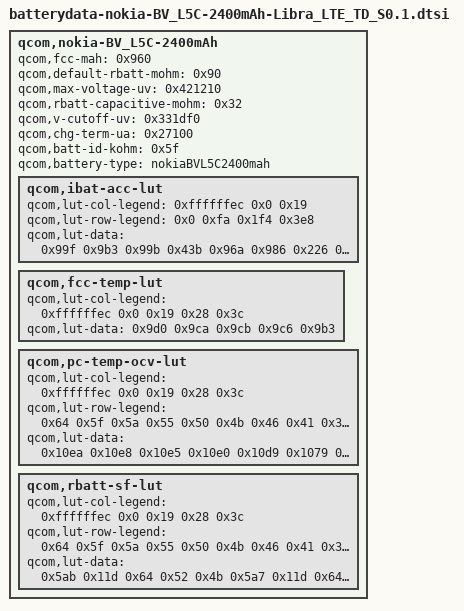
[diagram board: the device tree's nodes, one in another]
/* Copyright (c) 2013, The Linux Foundation. All rights reserved.
 *
 * This program is free software; you can redistribute it and/or modify
 * it under the terms of the GNU General Public License version 2 and
 * only version 2 as published by the Free Software Foundation.
 *
 * This program is distributed in the hope that it will be useful,
 * but WITHOUT ANY WARRANTY; without even the implied warranty of
 * MERCHANTABILITY or FITNESS FOR A PARTICULAR PURPOSE.  See the
 * GNU General Public License for more details.
 */

qcom,nokia-BV_L5C-2400mAh {
			qcom,fcc-mah = <0x960>;
			qcom,default-rbatt-mohm = <0x90>;
			qcom,max-voltage-uv = <0x421210>;
			qcom,rbatt-capacitive-mohm = <0x32>;
			qcom,v-cutoff-uv = <0x331df0>;
			qcom,chg-term-ua = <0x27100>;
			qcom,batt-id-kohm = <0x5f>;
			qcom,battery-type = "nokiaBVL5C2400mah";

			qcom,ibat-acc-lut {
				qcom,lut-col-legend = <0xffffffec 0x0 0x19>;
				qcom,lut-row-legend = <0x0 0xfa 0x1f4 0x3e8>;
				qcom,lut-data = <0x99f 0x9b3 0x99b 0x43b 0x96a 0x986 0x226 0x8b5 0x979 0x33 0x62e 0x954>;
			};

			qcom,fcc-temp-lut {
				qcom,lut-col-legend = <0xffffffec 0x0 0x19 0x28 0x3c>;
				qcom,lut-data = <0x9d0 0x9ca 0x9cb 0x9c6 0x9b3>;
			};

			qcom,pc-temp-ocv-lut {
				qcom,lut-col-legend = <0xffffffec 0x0 0x19 0x28 0x3c>;
				qcom,lut-row-legend = <0x64 0x5f 0x5a 0x55 0x50 0x4b 0x46 0x41 0x3c 0x37 0x32 0x2d 0x28 0x23 0x1e 0x19 0x14 0x10 0xd 0xb 0xa 0x9 0x8 0x7 0x6 0x5 0x4 0x3 0x2 0x1 0x0>;
				qcom,lut-data = <0x10ea 0x10e8 0x10e5 0x10e0 0x10d9 0x1079 0x1099 0x109e 0x109b 0x1096 0x1034 0x1060 0x1064 0x1062 0x105e 0xffe 0x102a 0x102c 0x102a 0x1026 0xfc8 0xff8 0xffa 0xff7 0xff2 0xf66 0xfc6 0xfcc 0xfc9 0xfc2 0xf3e 0xf72 0xf8e 0xf93 0xf96 0xf16 0xf4d 0xf72 0xf71 0xf6f 0xef6 0xf2e 0xf4a 0xf4c 0xf4a 0xee5 0xf0e 0xf1c 0xf22 0xf22 0xed8 0xef2 0xef9 0xefa 0xef8 0xecc 0xedc 0xee2 0xee2 0xee2 0xec0 0xecd 0xed2 0xed2 0xed0 0xeb4 0xec4 0xec4 0xec4 0xec2 0xea7 0xebc 0xebc 0xeb8 0xeb2 0xe98 0xeb2 0xeb4 0xeac 0xe9f 0xe88 0xea1 0xea4 0xe9a 0xe8b 0xe78 0xe88 0xe8a 0xe80 0xe73 0xe6a 0xe77 0xe6e 0xe65 0xe58 0xe5c 0xe70 0xe69 0xe62 0xe56 0xe55 0xe6d 0xe68 0xe61 0xe56 0xe4c 0xe6a 0xe67 0xe60 0xe54 0xe42 0xe68 0xe66 0xe5f 0xe54 0xe34 0xe65 0xe64 0xe5e 0xe52 0xe22 0xe60 0xe62 0xe5a 0xe4d 0xe0a 0xe54 0xe54 0xe4c 0xe3a 0xde8 0xe36 0xe2e 0xe21 0xe0f 0xdb6 0xdfb 0xdf0 0xde2 0xdd0 0xd65 0xda2 0xd94 0xd8c 0xd76 0xcce 0xd0e 0xcfd 0xcea 0xcdd 0xbb8 0xbb8 0xbb8 0xbb8 0xbb8>;
			};

			qcom,rbatt-sf-lut {
				qcom,lut-col-legend = <0xffffffec 0x0 0x19 0x28 0x3c>;
				qcom,lut-row-legend = <0x64 0x5f 0x5a 0x55 0x50 0x4b 0x46 0x41 0x3c 0x37 0x32 0x2d 0x28 0x23 0x1e 0x19 0x14 0x10 0xd 0xb 0xa 0x9 0x8 0x7 0x6 0x5 0x4 0x3 0x2 0x1>;
				qcom,lut-data = <0x5ab 0x11d 0x64 0x52 0x4b 0x5a7 0x11d 0x64 0x52 0x4b 0x53e 0x122 0x66 0x53 0x4c 0x4fa 0x126 0x69 0x56 0x4d 0x4c9 0x12a 0x6e 0x59 0x4e 0x450 0x139 0x75 0x5e 0x51 0x449 0x10d 0x77 0x5e 0x52 0x43d 0x10b 0x83 0x63 0x55 0x444 0x108 0x84 0x6b 0x5a 0x46b 0x101 0x71 0x65 0x5b 0x49d 0x101 0x65 0x54 0x4d 0x4d3 0x100 0x64 0x53 0x4e 0x50a 0x103 0x65 0x56 0x51 0x545 0x112 0x67 0x58 0x53 0x586 0x128 0x6b 0x59 0x51 0x5cb 0x13f 0x6e 0x57 0x4e 0x618 0x158 0x6b 0x55 0x4d 0x643 0x161 0x69 0x56 0x4d 0x5f1 0x154 0x65 0x52 0x4b 0x64b 0x16c 0x65 0x53 0x4c 0x685 0x17b 0x67 0x55 0x4e 0x6fa 0x18f 0x6a 0x57 0x4f 0x7be 0x1aa 0x6e 0x59 0x51 0x89d 0x1c8 0x70 0x5c 0x53 0x9cb 0x1e7 0x77 0x5e 0x54 0xb95 0x211 0x78 0x5e 0x53 0xe18 0x238 0x74 0x5a 0x50 0x1261 0x279 0x78 0x5d 0x54 0x1c4c 0x303 0x85 0x67 0x5c 0x84cc 0x1d51 0x80d 0x2db7 0xb5>;
			};
		};
